# CMU register map
Vendor: Texas Instruments
Peripheral module from a debugger description file (folder omap4460).
Registers are 32-bit, access per field, reset values left out (the file's numbers can be read two ways) unless marked. A register's access mark holds for its fields unless they carry their own. Offsets are as the file gives them; lines under a group give offsets from that group; [hi:lo] are bit positions; {n}, {i} and the like mark numbered series; 'fields as' and 'values as' point back to an identical list; <NAME> marks a mode.

## CMU
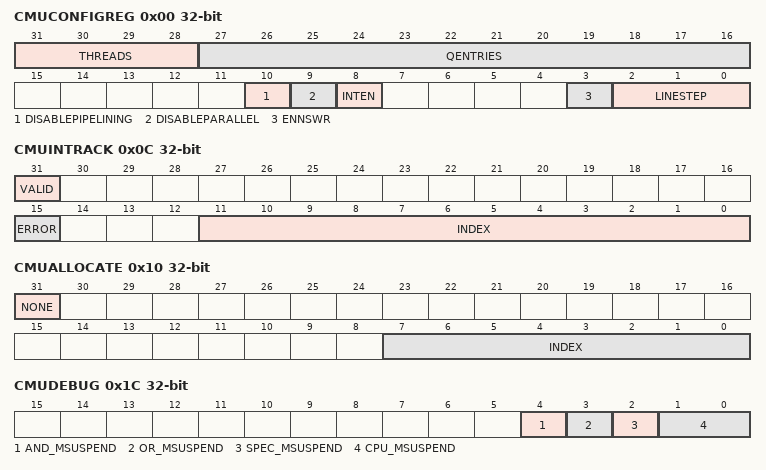
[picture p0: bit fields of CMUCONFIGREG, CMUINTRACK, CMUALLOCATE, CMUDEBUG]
0x00 CMUCONFIGREG — CMU Configuration Register
  [31:28] THREADS ro — Number of parallel CMO threads that can be simultaneously processed.
  [27:16] QENTRIES ro — Number of Queue Entries Configured
  [10] DISABLEPIPELINING rw — Disable pipelining of requests.
  [9] DISABLEPARALLEL rw — Force sequential operation by disabling any parallelism between RangeSets.
  [8] INTEN rw — Enable Interrupt on Set Completion. 0b0 = Don't interrupt. 0b1 = Interrupt on Completion.
  [3] ENNSWR rw — This enables Non-Safe programs to write this register. Out of reset - this bit is 0 which will prevent Non-Safe programs from writing it. Reading is always allowed. This bit can be set to 0x1 only through a Special Safe Monitor API. For more information about the API, see the Initialization chapter. The ROM Code will set this bit to 1 at boot time. The API can be used at runtime by the NS SW to enable/disable when necessary.
  [2:0] LINESTEP ro — Size of smallest cache line size, log2 - 2.
    0=Line Step = 4 bytes; 1=Line Step = 8 bytes; 2=Line Step = 16 bytes; 3=Line Step = 32 bytes; 4=Line Step = 64 bytes; 5=Line Step = 128 bytes; 6=Line Step = 256 bytes; 7=Line Step = 512 bytes
0x04 CMUSTATUSREG ro — CMU Status.
  [0] BUSY — Indicates that at least one set is active.0b0 = CMU is idle. 0b1 = At least one set is active.
0x0C CMUINTRACK ro — Interrupt Acknowledgment Register. Returns the index of the RangeSet that caused the interrupt. An error bit indicates an error completion.Since there is a queue of interrupt acknowledgments, there is also a valid bit that indicates that there were no more interrupts on the queue.
  [31] VALID — Indicates that the label field is valid. Can read the entire queue of entries by reading until get Valid = 0.
  [15] ERROR — Indicates that the RangeSet operation completed with an error.
  [11:0] INDEX — The index of the RangeSet that caused the interrupt.
0x10 CMUALLOCATE ro — Returns the index of a RangeSet in the Free state.
  [31] NONE — Returns 0b0 if Index is valid or 0b1 if no RangeSets available for allocation
  [7:0] INDEX — Returns the Index of a RangeSet if one is available or zero.
0x14 CMUDEALLOCATE — An index stored to this register frees the RangeSet with that index.
  [7:0] INDEX rw — RangeSet Index written here is deallocated (set to the Free state).
0x1C CMUDEBUG — Debug register to configure how MSuspend from the various CPUs need to be looked at by CMU to either send or not send traffic during debug session.
  [4] AND_MSUSPEND rw — This bit can be set so that only if all the MSuspends of all the CPUs present are enabled, CMU will suspend activity to ACP.Bits 3 and 2 need to be set to 0.
  [3] OR_MSUSPEND rw — This bit can be set so that if any of the MSuspends of CPUs present are enabled, then CMU will suspend activity to ACP.Bits 4 and 2 need to be 0.
  [2] SPEC_MSUSPEND rw — This bit enables CMU to look at the MSuspend of a specific CPU to suspend CMU activity to ACP.Bits 4, 3 need to be 0 when bit 2 is 1.
  [1:0] CPU_MSUSPEND rw — This field allows CMU to look at the MSuspend of a specific CPU to suspend traffic to ACP.When bit 4:2 = 3'b001, bits 1:0 indicates which CPU's MSuspend needs to be looked at. If the appropriate CPU's MSuspend is 1, then CMU will not generate any more activity to ACP and rest of system to have a non-intrusive debug session.When Bit 2 = 0, specific CPU's MSuspend cannot be used to control CMU's activity.
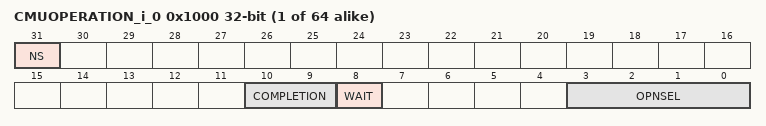
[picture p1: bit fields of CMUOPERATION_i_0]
{0x1000+0x10*i} CMUOPERATION_i_{i} access not given (i=0..63) — Controls the operation of one RangeSet of the CMU. Storing this register enqueues or activates the RangeSet.Note: must not write to any of the rangeset registers if State != 0b00. That indicates that previous values have not yet been transferred to the queue!
  [31] NS — Not Safe. Set to NS used to access StartPA register. Writing one to this bit will perform the operation as non-safe. The software can not clear this bit to 0x0 after. (access RW W1toSet)
  [10:9] COMPLETION rw — Completion Signaling Options:
    0=No notification of normal or error completion; 1=Interrupt on normal or error completion; 2=Interrupt on error but not normal completion
  [8] WAIT rw — Wait to start.0b1 = Wait until all previous requests are complete. 0b0 = may proceed in parallel with previous requests.
  [3:0] OPNSEL rw — Selects the Cache Management Operation.If an operation is started with a reserved OpnSel, the RangeSet is immediately moved to the Error state.
    0=No operation is performed. A RangeSet activated with this OpnSel is immediately moved to the completed state.; 1=Invalidate; 2=Clean; 3=Clean and Invalidate; 15=Always moves the RangeSet to the Error State
{0x1004+0x10*i} CMUSTARTPA_i_{i} rw (i=0..63) — Starting (lower, inclusive) 32-bit physical address.
  [31:0] STARTPA — Start of range for cache operations.
{0x1008+0x10*i} CMULENGTH_i_{i} (i=0..63) — Length in bytes of the range - 1, giving a representable range of 1 byte to 4k bytes.
  [11:0] LEN rw — Length of range minus 1.
{0x100C+0x10*i} CMURANGESTATE_i_{i} ro (i=0..63) — State of the Range Operation. Used to poll RangeSet for error or completion.
  [31:29] STATE — State of the RangeSet Request.
    0=STATE_0_r (RangeSet is unallocated.); 1=STATE_1_r (RangeSet allocated but not yet activated.); 2=STATE_2_r (Reserved); 3=STATE_3_r (RangeSet is active, either sequencing through cache lines, awaiting completion of earlier RangeSets or awaiting processing resources.); 4=STATE_4_r (Reserved); 5=STATE_5_r (Reserved); 6=STATE_6_r (RangeSet operation completed without errors.); 7=STATE_7_r (RangeSet encountered an error. Processing of the RangeSet stops with the first error. It is reported as complete with error.)
